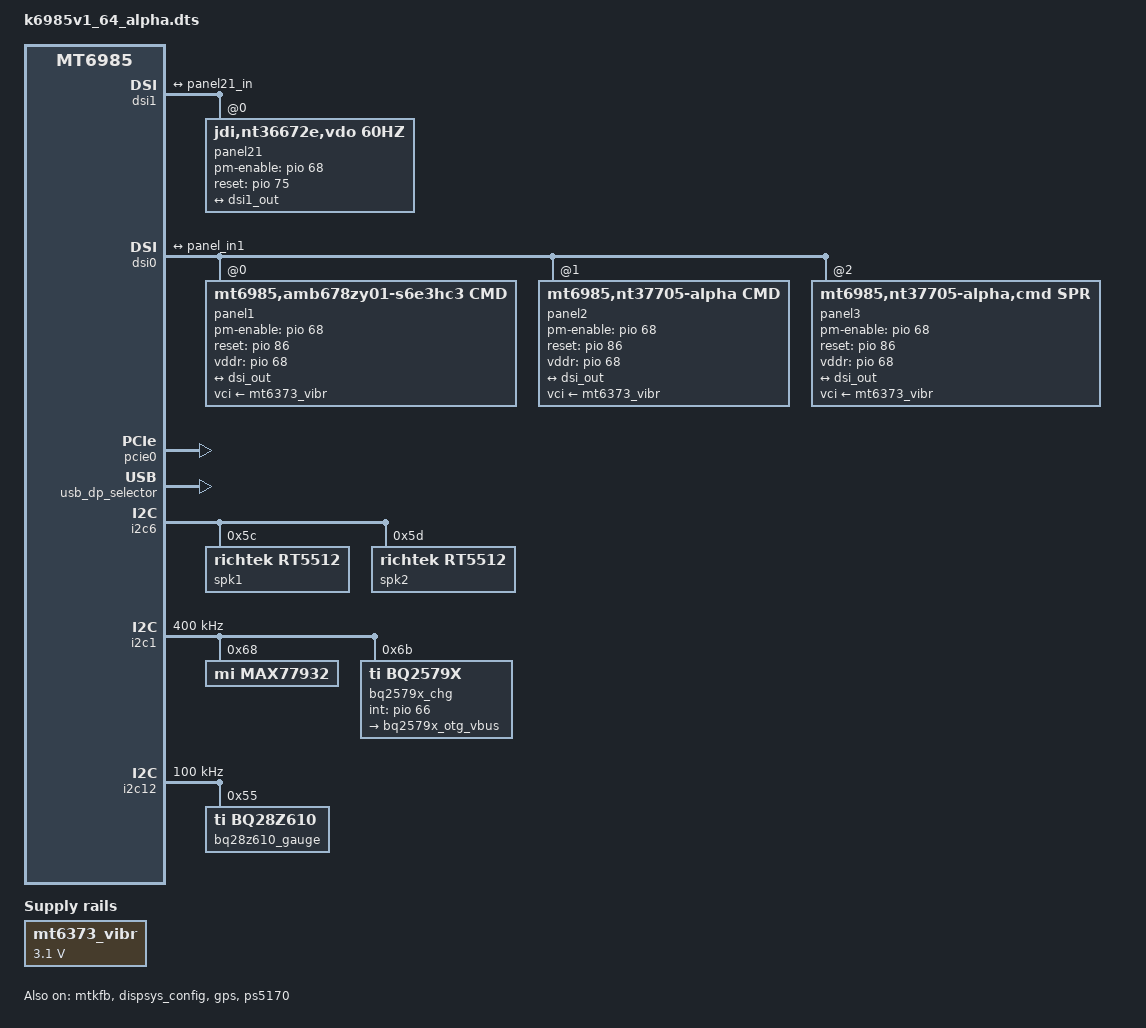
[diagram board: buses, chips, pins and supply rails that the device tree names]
// SPDX-License-Identifier: (GPL-2.0 OR MIT)
/*
 * Copyright (C) 2022 MediaTek Inc.
 */
/dts-v1/;
/plugin/;
#include <dt-bindings/interrupt-controller/arm-gic.h>
#include <dt-bindings/interrupt-controller/irq.h>
#include <dt-bindings/pinctrl/mt6985-pinfunc.h>
#include <dt-bindings/phy/phy.h>

&chosen {
bootargs_ext = "console=tty0 root=/dev/ram vmalloc=400M \
loglevel=8 \
androidboot.hardware=mt6985 \
8250.nr_uarts=4 \
initcall_debug=1";
};

&mtk_leds {
	compatible = "mediatek,disp-leds";

	backlight {
		max-brightness = <10239>;
		min-brightness = <4>;
		max-hw-brightness = <4095>;
		led_mode = <4>;
	};
};

&connfem {
	/* Support Wifi & BT ePA/eLNA FEM on customer load */
	epa_elna {
		parts = <&qm42639 &qm45639>;

		common {
			flags-0 {
				rx-mode = [81];
				fe-ant-cnt = [82];
				fe-main-bt-share-lp2g = [81];
				fe-conn-spdt = [8F];
				fe-reserved = [82];
			};
		};

		wifi {
			flags-0 {
				/* open-loop; */
			};
		};

		bt {
			flags-0 {
				/* choose one of: epa_elna/epa/elna/bypass */
				epa_elna;
			};
		};
	};
};

&pio {

	mtkfb_pins_lcm_rst_out1_gpio: lcm-rst-out1-gpio {
		pins-cmd-dat {
			pinmux = <PINMUX_GPIO86__FUNC_GPIO86>;
			slew-rate = <1>;
			output-high;
		};
	};

	mtkfb_pins_lcm_rst_out0_gpio: lcm-rst-out0-gpio {
		pins-cmd-dat {
			pinmux = <PINMUX_GPIO86__FUNC_GPIO86>;
			slew-rate = <1>;
			output-low;
		};
	};
	mtkfb_pins_lcm_dsi_te: lcm-dsi-te {
		pins-cmd-dat {
			pinmux = <PINMUX_GPIO85__FUNC_DSI_TE>;
		};
	};

	mtkfb_pins_lcm_vddr_out1_gpio: lcm-vddr-out1-gpio {
		pins-cmd-dat {
			pinmux = <PINMUX_GPIO68__FUNC_GPIO68>;
			slew-rate = <1>;
			output-high;
		};
	};

	mtkfb_pins_lcm_vddr_out0_gpio: lcm-vddr-out0-gpio {
		pins-cmd-dat {
			pinmux = <PINMUX_GPIO68__FUNC_GPIO68>;
			slew-rate = <1>;
			output-low;
		};
	};
	mtkfb_pins_nvt_en_0p8_out1_gpio: nvt-en-0p8-out1-gpio {
		pins-cmd-dat {
			pinmux = <PINMUX_GPIO69__FUNC_GPIO69>;
			slew-rate = <1>;
			output-high;
		};
	};
	mtkfb_pins_nvt_en_0p8_out0_gpio: nvt-en-0p8-out0-gpio {
		pins-cmd-dat {
			pinmux = <PINMUX_GPIO69__FUNC_GPIO69>;
			slew-rate = <1>;
			output-low;
		};
	};

	mtkfb_pins_nvt_en_1p8_out1_gpio: nvt-en-1p8-out1-gpio {
		pins-cmd-dat {
			pinmux = <PINMUX_GPIO120__FUNC_GPIO120>;
			slew-rate = <1>;
			output-high;
		};
	};

	mtkfb_pins_nvt_en_1p8_out0_gpio: nvt-en-1p8-out0-gpio {
		pins-cmd-dat {
			pinmux = <PINMUX_GPIO120__FUNC_GPIO120>;
			slew-rate = <1>;
			output-low;
		};
	};
};

&mtkfb {
	pinctrl-names =
		"lcm-rst-out1-gpio", "lcm-rst-out0-gpio",
		"lcm-dsi-te", "lcm-vddr-out1-gpio",
		"lcm-vddr-out0-gpio", "nvt-en-0p8-out1-gpio",
		"nvt-en-0p8-out0-gpio", "nvt-en-1p8-out1-gpio",
		"nvt-en-1p8-out0-gpio";
	pinctrl-0 = <&mtkfb_pins_lcm_rst_out1_gpio>;
	pinctrl-1 = <&mtkfb_pins_lcm_rst_out0_gpio>;
	pinctrl-2 = <&mtkfb_pins_lcm_dsi_te>;
	pinctrl-3 = <&mtkfb_pins_lcm_vddr_out1_gpio>;
	pinctrl-4 = <&mtkfb_pins_lcm_vddr_out0_gpio>;
	pinctrl-5 = <&mtkfb_pins_nvt_en_0p8_out1_gpio>;
	pinctrl-6 = <&mtkfb_pins_nvt_en_0p8_out0_gpio>;
	pinctrl-7 = <&mtkfb_pins_nvt_en_1p8_out1_gpio>;
	pinctrl-8 = <&mtkfb_pins_nvt_en_1p8_out0_gpio>;
	status = "okay";
};

&dispsys_config {
	pinctrl-names = "mode_te_te";
	pinctrl-0 = <&mtkfb_pins_lcm_dsi_te>;
	status = "okay";
};

&dsi1 {
//	status = "okay";
	#address-cells = <1>;
	#size-cells = <0>;
	panel21@0 {
		compatible = "jdi,nt36672e,vdo,60hz";
		reg = <0>;
		pm-enable-gpios = <&pio 68 0>;
		reset-gpios = <&pio 75 0>;
		gate-ic = <4831>;
		pinctrl-names = "default";
		port {
			panel21_in: endpoint {
				remote-endpoint = <&dsi1_out>;
			};
		};
	};
	ports {
		port {
			dsi1_out: endpoint {
				remote-endpoint = <&panel21_in>;
			};
		};
	};
};

&dsi0 {
	status = "okay";
	#address-cells = <1>;
	#size-cells = <0>;
	switch-spr = <0>;
	panel1@0 {
		compatible = "mt6985,amb678zy01-s6e3hc3,cmd";
		reg = <0>;
		pm-enable-gpios = <&pio 68 0>;
		reset-gpios = <&pio 86 0>;
		vddr-gpios = <&pio 68 0>;
		vci-supply = <&mt6373_vibr>;
		gate-ic = <4831>;
		pinctrl-names = "default";
		port {
			panel_in1: endpoint {
				remote-endpoint = <&dsi_out>;
			};
		};
	};
	panel2@0 {
		compatible = "mt6985,nt37705-alpha,cmd";
		reg = <1>;
		pm-enable-gpios = <&pio 68 0>;
		reset-gpios = <&pio 86 0>;
		vddr-gpios = <&pio 68 0>;
		vci-supply = <&mt6373_vibr>;
		gate-ic = <4831>;
		pinctrl-names = "default";
		port {
			panel_in2: endpoint {
				remote-endpoint = <&dsi_out>;
			};
		};
	};
	panel3@0 {
		compatible = "mt6985,nt37705-alpha,cmd,spr";
		reg = <2>;
		pm-enable-gpios = <&pio 68 0>;
		reset-gpios = <&pio 86 0>;
		vddr-gpios = <&pio 68 0>;
		vci-supply = <&mt6373_vibr>;
		gate-ic = <4831>;
		pinctrl-names = "default";
		port {
			panel_in3: endpoint {
				remote-endpoint = <&dsi_out>;
			};
		};
	};
	ports {
		port {
			dsi_out: endpoint {
				remote-endpoint = <&panel_in1>;
			};
		};
	};
};
/* GPS GPIO standardization start */

&mt6373_vibr {
		regulator-min-microvolt = <3100000>;
		regulator-max-microvolt = <3100000>;
		regulator-always-on;
};

&pio {
	gps_pins_default: gps_default {
	};
	gps_l1_lna_pins_ol: gps-l1-lna0 {
		pins-cmd-dat {
			pinmux = <PINMUX_GPIO16__FUNC_GPIO16>;
			output-low;
		};
	};
	gps_l1_lna_pins_dsp_ctrl: gps-l1-lna1 {
		pins-cmd-dat {
			pinmux = <PINMUX_GPIO16__FUNC_GPS_L1_ELNA_EN>;
		};
	};
	gps_l1_lna_pins_oh: gps-l1-lna2 {
		pins-cmd-dat {
			pinmux = <PINMUX_GPIO16__FUNC_GPIO16>;
			output-high;
		};
	};
	gps_l5_lna_pins_ol: gps-l5-lna0 {
		pins-cmd-dat {
			pinmux = <PINMUX_GPIO17__FUNC_GPIO17>;
			output-low;
		};
	};
	gps_l5_lna_pins_dsp_ctrl: gps-l5-lna1 {
		pins-cmd-dat {
			pinmux = <PINMUX_GPIO17__FUNC_GPS_L5_ELNA_EN>;
		};
	};
	gps_l5_lna_pins_oh: gps-l5-lna2 {
		pins-cmd-dat {
			pinmux = <PINMUX_GPIO17__FUNC_GPIO17>;
			output-high;
		};
	};
};
&gps {
	pinctrl-names = "default",
		"gps_l1_lna_disable",
		"gps_l1_lna_dsp_ctrl",
		"gps_l1_lna_enable",
		"gps_l5_lna_disable",
		"gps_l5_lna_dsp_ctrl",
		"gps_l5_lna_enable";
	pinctrl-0 = <&gps_pins_default>;
	pinctrl-1 = <&gps_l1_lna_pins_ol>;
	pinctrl-2 = <&gps_l1_lna_pins_dsp_ctrl>;
	pinctrl-3 = <&gps_l1_lna_pins_oh>;
	pinctrl-4 = <&gps_l5_lna_pins_ol>;
	pinctrl-5 = <&gps_l5_lna_pins_dsp_ctrl>;
	pinctrl-6 = <&gps_l5_lna_pins_oh>;
	status = "okay";
};
/* GPS GPIO standardization end */

/* PCIe pinmux start */
&pcie0 {
	pinctrl-names = "default", "sleep";
	pinctrl-0 = <&pcie0_pins_default>;
	pinctrl-1 = <&pcie0_pins_sleep>;
	status = "okay";
};

&pcie1 {
	pinctrl-names = "default";
	pinctrl-0 = <&pcie1_pins_default>;
	status = "disabled";
};

&pio {
	pcie0_pins_default: pcie0-default {
		pins_cmd_dat {
			/* PINMUX_GPIO231__FUNC_PCIE_WAKEN for Falcon */
			pinmux = <PINMUX_GPIO230__FUNC_PCIE_PERSTN>,
				 <PINMUX_GPIO232__FUNC_PCIE_CLKREQN>;
			bias-pull-up;
		};
	};

	pcie0_pins_sleep: pcie0-sleep {
		pins_cmd_dat {
			/* PINMUX_GPIO231__FUNC_GPIO231 for Falcon */
			pinmux = <PINMUX_GPIO230__FUNC_GPIO230>,
				 <PINMUX_GPIO232__FUNC_GPIO232>;
			bias-pull-down;
			input-enable;
		};
	};

	pcie1_pins_default: pcie1-default {
		pins_cmd_dat {
			pinmux = <PINMUX_GPIO0__FUNC_PCIE_PERSTN_P1>,
				 <PINMUX_GPIO1__FUNC_PCIE_WAKEN_P1>,
				 <PINMUX_GPIO2__FUNC_PCIE_CLKREQN_P1>;
			bias-pull-up;
		};
	};
};
/* PCIe pinmux end */

/* usb typec mux start */
&pio {

	ps_enable: ps_enable {
		pins_cmd_dat {
			pinmux = <PINMUX_GPIO204__FUNC_GPIO204>;
			output-high;
		};
	};

	ps_disable: ps_disable {
		pins_cmd_dat {
			pinmux = <PINMUX_GPIO204__FUNC_GPIO204>;
			output-low;
		};
	};

};

&mt6375_typec {
	port {
		tcpc_typec_usb: endpoint {
			remote-endpoint = <&ssusb_mux>;
		};
	};
};

&typec_mux_switch {
	orientation-switch;
	mode-switch;
	accessory;
	port {
		ssusb_mux: endpoint {
			remote-endpoint = <&tcpc_typec_usb>;
		};
	};
};

&ps5170 {
	pinctrl-names = "enable", "disable";
	pinctrl-0 = <&ps_enable>;
	pinctrl-1 = <&ps_disable>;
	status = "okay";
};

&usb_dp_selector {
	status = "okay";
};
/* usb typec mux end */

#include "mediatek/cust_mt6985_touch_samsung_y761_1440x3200.dtsi"
#include "mediatek/cust_mt6985_touch_gt9916_1080_2376.dtsi"

&i2c6 {
	spk1: speaker_amp@5c {
		compatible = "richtek,rt5512";
		#sound-dai-cells = <0>;
		reg = <0x5c>;
		status = "okay";
		sound-name-prefix = "Left";
	};

	spk2: speaker_amp@5d {
		compatible = "richtek,rt5512";
		#sound-dai-cells = <0>;
		reg = <0x5d>;
		status = "okay";
		sound-name-prefix = "Right";
	};
};

&sound {
	mediatek,spk-i2s = <3 9>;
	mediatek,speaker-codec {
		sound-dai = <&spk1>, <&spk2>;
	};
};

&pdc {
	pd_vbus_upper_bound = <12000000>;
};

&mt6363keys {
	home {
		linux,keycodes = <114>;
	};
};

&lk_charger {
	/* disable_charger; */
	/* boot_battery_voltage = <3600000>; */
	usb_charger_current = <1000000>;
};

&charger {
	enable_vbat_mon = <0>;

	gauge = <&bq28z610_gauge>;
	charger = <&bq2579x_chg>;
	bc12_psy = <&mt6375_chg>;
};

&i2c1 {
	status = "okay";
	#address-cells = <1>;
	#size-cells = <0>;
	clock-frequency = <400000>;
	mediatek,use-open-drain;

	max77932@68 {
		compatible = "mi,max77932";
		reg = <0x68>;
	};

	bq2579x_chg: bq2579x@6b {
		compatible = "ti,bq2579x";
		reg = <0x6b>;

		alpha,int-gpio = <&pio 66 0>;
		//alpha,enable-gpio = <&pio 69 0>;

		bq2579x_otg_vbus: otg {
			regulator-compatible = "bq2579x,otg-vbus";
			regulator-name = "usb-otg-vbus";
		};
	};
};

&extcon_usb {
	/* charger = <&bq2579x_chg>; */
	/* /delete-property/ vbus-supply; */
	vbus-supply;
};

&extcon_usb1 {
	status = "disabled";
};

&mtk_gauge {
	DISABLE_MTKBATTERY = <(1)>;
};

&i2c12 {
	status = "okay";
	#address-cells = <1>;
	#size-cells = <0>;
	clock-frequency = <100000>;
	mediatek,use-open-drain;
	scl-gpio-id = <211>;
	sda-gpio-id = <212>;

	bq28z610_gauge: bq28z610@55 {
		compatible = "ti,bq28z610";
		reg = <0x55>;
	};
};

&i2c5 {
	rt1711_typec: rt1711h@4e {
		compatible = "richtek,rt1711h";
		reg = <0x4e>;
		status = "disabled";
		rt-tcpc,name = "type_c_port0"; /* tcpc_device's name */
		rt-tcpc,role_def = <5>; /* 0: Unknown, 1: SNK, 2: SRC */
					/* 3: DRP, 4: Try.SRC, 5: Try.SNK */
		rt-tcpc,rp_level = <0>; /* 0: Default, 1: 1.5, 2: 3.0 */
		rt-tcpc,vconn_supply = <1>;  /* 0: Never, 1: Always, */
					     /* 2: EMarkOnly, 3: StartOnly */
		rt1711pd,intr_gpio = <&pio 41 0x0>;
		rt1711pd,intr_gpio_num = <41>;
		/* charger = <&mt6375_chg>; */
		pd-data {
			pd,vid = <0x29cf>;
			pd,pid = <0x1711>;
			pd,source-cap-ext = /bits/ 8 <0xcf 0x29 0x11 0x17
						      0x00 0x00 0x00 0x00
						      0x00 0x00 0x00 0x00
						      0x00 0x00 0x00 0x00
						      0x00 0x00 0x00 0x00
						      0x00 0x00 0x01 0x02
						      0x00>;
			pd,sink-cap-ext = /bits/ 8 <0xcf 0x29 0x11 0x17
						    0x00 0x00 0x00 0x00
						    0x00 0x00 0x01 0x00
						    0x00 0x00 0x00 0x00
						    0x01 0x0b 0x01 0x0a
						    0x0a 0x00 0x00 0x00>;
			pd,mfrs = "RichtekTCPC";

			/*
			 *	VSAFE5V = 0, MAX_POWER = 1, CUSTOM = 2,
			 *	MAX_POWER_LV = 0x21, MAX_POWER_LVIC = 0x31
			 *	MAX_POWER_HV = 0x41, MAX_POWER_HVIC = 0x51
			 */
			pd,charging_policy = <0x31>;

			/*
			 * Fixed 5V, 500 mA <0x00019032>
			 * Fixed 5V, 1A <0x00019064>
			 * Fixed 5V, 2A <0x000190c8>
			 * Fixed 5V, 3A <0x0001912c>
			 * Fixed 9V, 500 mA <0x0002d032>
			 * Fixed 9V, 1A <0x0002d064>
			 * Fixed 9V, 2A <0x0002d0c8>
			 * Fixed 9V, 3A <0x0002d12c>
			 * Variable 5-9V, 1A <0x8642d064>
			 * Variable 5-9V, 2A <0x8642d0c8>
			 * Variable 5-9V, 3A <0x8642d12c>
			 */
			pd,source-pdo-size = <1>;
			pd,source-pdo-data = <0x00019032>;
			pd,sink-pdo-size = <1>;
			pd,sink-pdo-data = <0x000190c8>;

			/*
			 * No DP, host + device
			 *	pd,id-vdo-size = <6>;
			 *	pd,id-vdo-data = <0xd14029cf 0x0 0x17110000
						  0x61000000 0x0 0x41000000>;
			 * With DP
			 *	pd,id-vdo-size = <6>;
			 *	pd,id-vdo-data = <0xd54029cf 0x0 0x17110000
						  0x61000000 0x0 0x41000000>;
			 */

			pd,id-vdo-size = <6>;
			pd,id-vdo-data = <0xd14029cf 0x0 0x17110000
					  0x61000000 0x0 0x41000000>;

			bat,nr = <1>;
			pd,country_nr = <0>;

			bat-info0 {
				bat,vid = <0x29cf>;
				bat,pid = <0x1711>;
				bat,mfrs = "bat1";
				bat,design_cap = <3000>;
			};

			//bat-info1 {
			//	bat,vid = <0x8abc>;
			//	bat,pid = <0x5234>;
			//	bat,mfrs = "bat2";
			//	bat,design_cap = <4000>;
			//};

			//country0 {
			//	pd,country_code = <0x5457>;
			//	pd,country_len = <2>; /* max len = 26 */
			//	pd,country_data = <0xff 0xff>;
			//};

			//country1 {
			//	pd,country_code = <0x5553>;
			//	pd,country_len = <3>; /* max len = 26 */
			//	pd,country_data = <0xf1 0xf2 0xf3>;
			//};
		};
		dpm_caps {
			local_dr_power;
			local_dr_data;
			//local_ext_power;
			local_usb_comm;
			//local_usb_suspend;
			//local_high_cap;
			//local_give_back;
			local_no_suspend;

			// attempt_discover_cable_dfp;
			attempt_enter_dp_mode;
			attempt_discover_cable;
			// attempt_discover_id;
			// attempt_discover_svid;

			/* 0: disable, 1: prefer_snk, 2: prefer_src */
			pr_check = <0>;
			//pr_reject_as_source;
			//pr_reject_as_sink;
			//pr_check_gp_source;
			//pr_check_gp_sink;

			/* 0: disable, 1: prefer_ufp, 2: prefer_dfp */
			dr_check = <0>;
			//dr_reject_as_dfp;
			//dr_reject_as_ufp;
		};
		displayport {
			/* connection type = "both", "ufp_d", "dfp_d" */
			1st_connection = "dfp_d";
			2nd_connection = "dfp_d";
			signal,dp_v13;
			//signal,dp_gen2;
			//usbr20_not_used;
			typec,receptacle;
			ufp_d {
				//pin_assignment,mode_c;
				//pin_assignment,mode_d;
				//pin_assignment,mode_e;
			};
			dfp_d {
				pin_assignment,mode_c;
				pin_assignment,mode_d;
				pin_assignment,mode_e;
			};
		};
	};
};

&mddriver {
	ref-args = "md_disable";
};

&mmc1 {
	status = "disabled";
};

#include "mediatek/cust_k6985_connfem.dtsi"
#include "mediatek/cust_mt6985_alpha_camera_v4l2.dtsi"
#include <k6985v1_64_alpha/cust.dtsi>
/*End of this file, DO NOT ADD ANYTHING HERE*/

